# TC37X register map
File version: 1.0.0
CPU: CM4 r0p1, little endian, MPU, FPU, VTOR, 3 interrupt priority bits
Registers are 16-bit, read-write, reset 0x0 unless marked. A register's access mark holds for its fields unless they carry their own. Offsets are from the block's base; [hi:lo] are bit positions; lines under a group give offsets from that group; {n}, {i} and the like mark numbered series; 'fields as' and 'values as' point back to an identical list.

## SMU — ce_smu
Base 0xF0036800
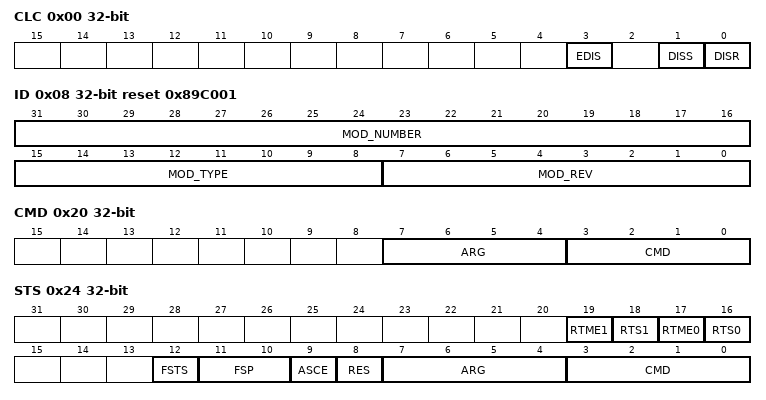
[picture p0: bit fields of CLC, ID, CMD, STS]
0x00 CLC 32-bit — Clock Control Register
  [3] EDIS — Sleep Mode Enable Control - EDIS
  [1] DISS ro — Module Disable Status Bit - DISS
  [0] DISR — Module Disable Request Bit - DISR
0x08 ID 32-bit ro reset 0x89C001 — Module Identification Register
  [31:16] MOD_NUMBER — Module Number Value - MOD_NUMBER
  [15:8] MOD_TYPE — Module Type - MOD_TYPE
  [7:0] MOD_REV — Module Revision Number - MOD_REV
0x20 CMD 32-bit wo — Command Register
  [7:4] ARG — Implements the SMU_core Command Interface. - ARG
  [3:0] CMD — Implements the SMU_core Command Interface. - CMD
0x24 STS 32-bit (reset mask 0xFFFFF3FF) — Status Register
  [19] RTME1 — Recovery Timer 1 Missed Event - RTME1
  [18] RTS1 — Recovery Timer 1 Status - RTS1
  [17] RTME0 — Recovery Timer 0 Missed Event - RTME0
  [16] RTS0 — Recovery Timer 0 Status - RTS0
  [12] FSTS — Fault State Timing Status - FSTS
  [11:10] FSP ro — Fault Signaling Protocol status - FSP
  [9] ASCE — Alarm Status Clear Enable - ASCE
  [8] RES — Result of last received command - RES
  [7:4] ARG — Last command argument received - ARG
  [3:0] CMD — Last command received - CMD
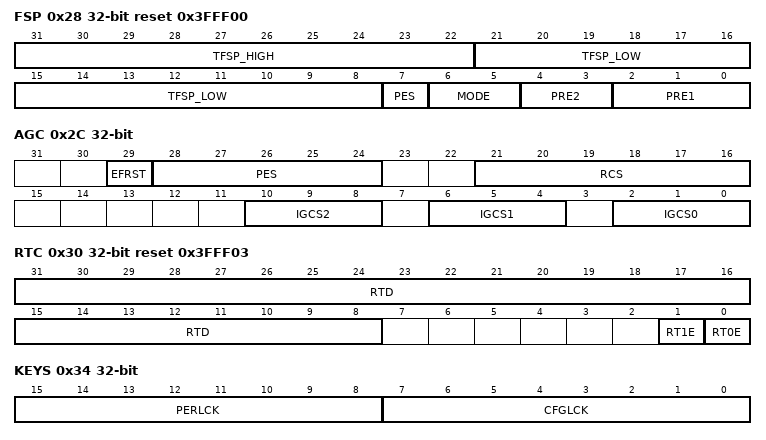
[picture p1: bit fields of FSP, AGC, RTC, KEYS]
0x28 FSP 32-bit reset 0x3FFF00 — Fault Signaling Protocol
  [31:22] TFSP_HIGH — Specifies the FSP fault state duration - TFSP_HIGH
  [21:8] TFSP_LOW ro — Specifies the FSP fault state duration - TFSP_LOW
  [7] PES — Port Emergency Stop (PES) - PES
  [6:5] MODE — Fault Signaling Protocol configuration - MODE
  [4:3] PRE2 — Prescaler2 - PRE2
  [2:0] PRE1 — Prescaler1 - PRE1
0x2C AGC 32-bit — Alarm Global Configuration
  [29] EFRST — Enable FAULT to RUN State Transition - EFRST
  [28:24] PES — Port Emergency Stop - PES
  [21:16] RCS — CPU Reset Configuration Set - RCS
  [10:8] IGCS2 — Interrupt Generation Configuration Set 2 - IGCS2
  [6:4] IGCS1 — Interrupt Generation Configuration Set 1 - IGCS1
  [2:0] IGCS0 — Interrupt Generation Configuration Set 0 - IGCS0
0x30 RTC 32-bit reset 0x3FFF03 — Recovery Timer Configuration
  [31:8] RTD — Recovery Timer Duration - RTD
  [1] RT1E — RT1 Enable Bit - RT1E
  [0] RT0E — RT0 Enable Bit - RT0E
0x34 KEYS 32-bit — Key Register
  [15:8] PERLCK — Permanent Lock - PERLCK
  [7:0] CFGLCK — Configuration Lock - CFGLCK
0x38 DBG 32-bit ro — Debug Register
  [1:0] SSM — Running state of the SMU_core State Machine - SSM
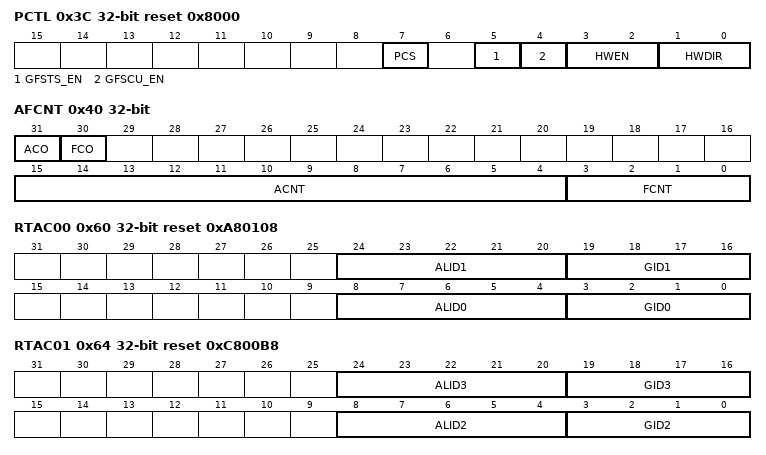
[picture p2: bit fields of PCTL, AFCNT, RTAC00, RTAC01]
0x3C PCTL 32-bit reset 0x8000 — Port Control
  [7] PCS — PAD Configuration Select - PCS
  [5] GFSTS_EN — Glitch Filter for ErrorPin SMU_FSP0 to register SMU_STS enable - GFSTS_EN
  [4] GFSCU_EN — Glitch Filter for ErrorPin SMU_FSP0 to SCU enable - GFSCU_EN
  [3:2] HWEN — Port Enable - HWEN
  [1:0] HWDIR — Port Direction. - HWDIR
0x40 AFCNT 32-bit ro — Alarm and Fault Counter
  [31] ACO — Alarm Counter Overflow. - ACO
  [30] FCO — Fault Counter Overflow. - FCO
  [15:4] ACNT — Alarm Counter. - ACNT
  [3:0] FCNT — Fault Counter. - FCNT
0x60 RTAC00 32-bit reset 0xA80108 — Recovery Timer 0 Alarm Configuration 0
  [24:20] ALID1 — Alarm Identifier 1. - ALID1
  [19:16] GID1 — Group Index 1. - GID1
  [8:4] ALID0 — Alarm Identifier 0. - ALID0
  [3:0] GID0 — Group Index 0. - GID0
0x64 RTAC01 32-bit reset 0xC800B8 — Recovery Timer 0 Alarm Configuration 1
  [24:20] ALID3 — Alarm Identifier 1. - ALID3
  [19:16] GID3 — Group Index 3. - GID3
  [8:4] ALID2 — Alarm Identifier 0. - ALID2
  [3:0] GID2 — Group Index 2. - GID2
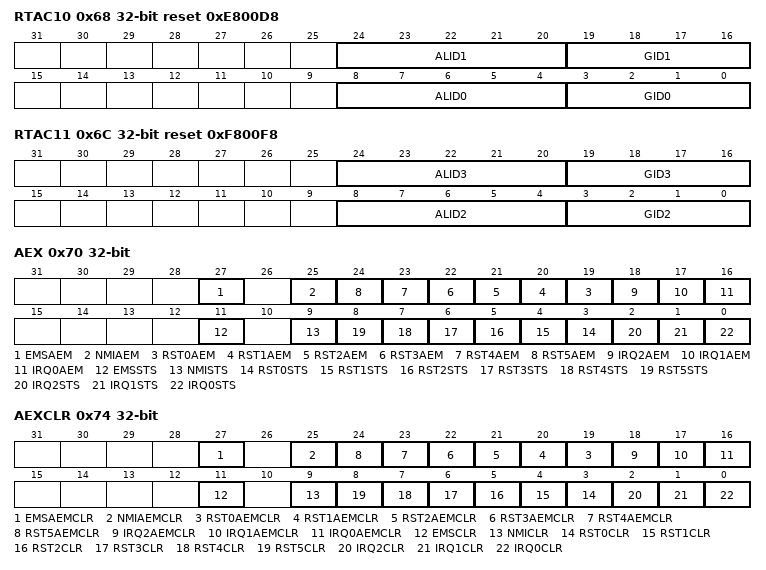
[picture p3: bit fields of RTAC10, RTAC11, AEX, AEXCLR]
0x68 RTAC10 32-bit reset 0xE800D8 — Recovery Timer 1 Alarm Configuration 0
  fields as RTAC00
0x6C RTAC11 32-bit reset 0xF800F8 — Recovery Timer 1 Alarm Configuration 1
  [24:20] ALID3 — Alarm Identifier 3. - ALID3
  [19:16] GID3 — Group Index 3. - GID3
  [8:4] ALID2 — Alarm Identifier 2. - ALID2
  [3:0] GID2 — Group Index 2. - GID2
0x70 AEX 32-bit ro — Alarm Executed Status Register
  [27] EMSAEM — EMS AEM - EMSAEM
  [25] NMIAEM — NMI AEM - NMIAEM
  [n+19] RST{n}AEM (n=0..5) — RST{n} AEM - RST{n}AEM
  [18] IRQ2AEM — IRQ2 AEM - IRQ2AEM
  [17] IRQ1AEM — IRQ1 AEM - IRQ1AEM
  [16] IRQ0AEM — IRQ0 AEM - IRQ0AEM
  [11] EMSSTS — EMS Request Status - EMSSTS
  [9] NMISTS — NMI Request Status - NMISTS
  [n+3] RST{n}STS (n=0..5) — RST{n} Request Status - RST{n}STS
  [2] IRQ2STS — IRQ2 Request Status - IRQ2STS
  [1] IRQ1STS — IRQ1 Request Status - IRQ1STS
  [0] IRQ0STS — IRQ0 Request Status - IRQ0STS
0x74 AEXCLR 32-bit wo — Alarm Executed Status Clear Register
  [27] EMSAEMCLR — EMS AEM Status Clear - EMSAEMCLR
  [25] NMIAEMCLR — NMI AEM Status Clear - NMIAEMCLR
  [n+19] RST{n}AEMCLR (n=0..5) — RST{n} AEM Status Clear - RST{n}AEMCLR
  [18] IRQ2AEMCLR — IRQ2 AEM Status Clear - IRQ2AEMCLR
  [17] IRQ1AEMCLR — IRQ1 AEM Status Clear - IRQ1AEMCLR
  [16] IRQ0AEMCLR — IRQ0 AEM Status Clear - IRQ0AEMCLR
  [11] EMSCLR — EMS Request Status Clear - EMSCLR
  [9] NMICLR — NMI Request Status Clear - NMICLR
  [n+3] RST{n}CLR (n=0..5) — RST{n} Request Status Clear - RST{n}CLR
  [2] IRQ2CLR — IRQ2 Request Status Clear - IRQ2CLR
  [1] IRQ1CLR — IRQ1 Request Status Clear - IRQ1CLR
  [0] IRQ0CLR — IRQ0 Request Status Clear - IRQ0CLR
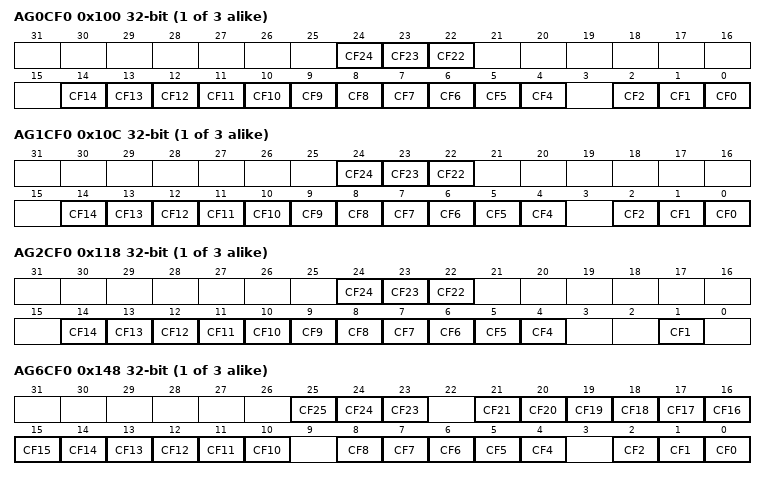
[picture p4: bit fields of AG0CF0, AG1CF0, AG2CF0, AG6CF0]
{0x100+4i} AG0CF{i} 32-bit (i=0..2) — Alarm Configuration Register
  [24] CF24 — Configuration flag x (x=0-2) for alarm 24 belonging to alarm group i. - CF24
  [23] CF23 — Configuration flag x (x=0-2) for alarm 23 belonging to alarm group i. - CF23
  [22] CF22 — Configuration flag x (x=0-2) for alarm 22 belonging to alarm group i. - CF22
  [n] CF{n} (n=4..14) — Configuration flag x (x=0-2) for alarm {n} belonging to alarm group i. - CF{n}
  [2] CF2 — Configuration flag x (x=0-2) for alarm 2 belonging to alarm group i. - CF2
  [1] CF1 — Configuration flag x (x=0-2) for alarm 1 belonging to alarm group i. - CF1
  [0] CF0 — Configuration flag x (x=0-2) for alarm 0 belonging to alarm group i. - CF0
{0x10C+4i} AG1CF{i} 32-bit (i=0..2) — Alarm Configuration Register
  fields as AG0CF0
{0x118+4i} AG2CF{i} 32-bit (i=0..2) — Alarm Configuration Register
  [24] CF24 — Configuration flag x (x=0-2) for alarm 24 belonging to alarm group i. - CF24
  [23] CF23 — Configuration flag x (x=0-2) for alarm 23 belonging to alarm group i. - CF23
  [22] CF22 — Configuration flag x (x=0-2) for alarm 22 belonging to alarm group i. - CF22
  [n] CF{n} (n=4..14) — Configuration flag x (x=0-2) for alarm {n} belonging to alarm group i. - CF{n}
  [1] CF1 — Configuration flag x (x=0-2) for alarm 1 belonging to alarm group i. - CF1
{0x100+0xC*i} AG{i}CF0 32-bit ro (i=3..5) — Alarm Configuration Register
{0x104+0xC*i} AG{i}CF1 32-bit ro (i=3..5) — Alarm Configuration Register
{0x108+0xC*i} AG{i}CF2 32-bit ro (i=3..5) — Alarm Configuration Register
{0x148+4i} AG6CF{i} 32-bit (i=0..2) — Alarm Configuration Register
  [25] CF25 — Configuration flag x (x=0-2) for alarm 25 belonging to alarm group i. - CF25
  [24] CF24 — Configuration flag x (x=0-2) for alarm 24 belonging to alarm group i. - CF24
  [23] CF23 — Configuration flag x (x=0-2) for alarm 23 belonging to alarm group i. - CF23
  [n] CF{n} (n=10..21) — Configuration flag x (x=0-2) for alarm {n} belonging to alarm group i. - CF{n}
  [n] CF{n} (n=4..8) — Configuration flag x (x=0-2) for alarm {n} belonging to alarm group i. - CF{n}
  [2] CF2 — Configuration flag x (x=0-2) for alarm 2 belonging to alarm group i. - CF2
  [1] CF1 — Configuration flag x (x=0-2) for alarm 1 belonging to alarm group i. - CF1
  [0] CF0 — Configuration flag x (x=0-2) for alarm 0 belonging to alarm group i. - CF0
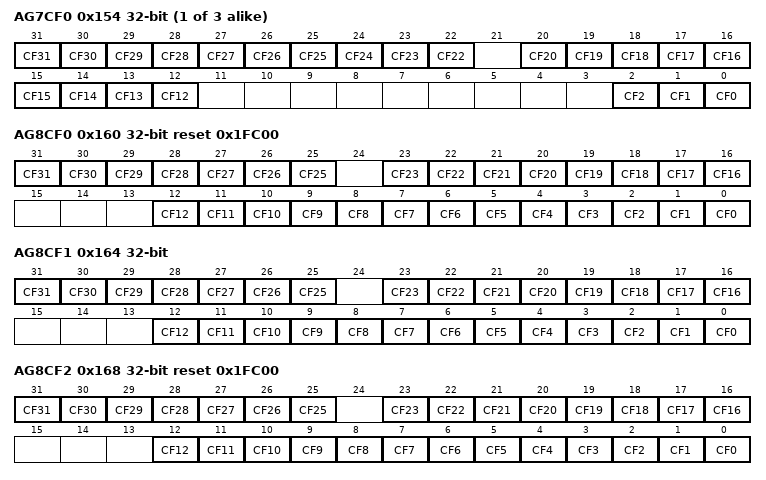
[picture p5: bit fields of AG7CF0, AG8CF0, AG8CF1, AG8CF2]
{0x154+4i} AG7CF{i} 32-bit (i=0..2) — Alarm Configuration Register
  [n] CF{n} (n=22..31) — Configuration flag x (x=0-2) for alarm {n} belonging to alarm group i. - CF{n}
  [n] CF{n} (n=12..20) — Configuration flag x (x=0-2) for alarm {n} belonging to alarm group i. - CF{n}
  [2] CF2 — Configuration flag x (x=0-2) for alarm 2 belonging to alarm group i. - CF2
  [1] CF1 — Configuration flag x (x=0-2) for alarm 1 belonging to alarm group i. - CF1
  [0] CF0 — Configuration flag x (x=0-2) for alarm 0 belonging to alarm group i. - CF0
0x160 AG8CF0 32-bit reset 0x1FC00 — Alarm Configuration Register
  [n] CF{n} (n=25..31) — Configuration flag x (x=0-2) for alarm {n} belonging to alarm group i. - CF{n}
  [n] CF{n} (n=16..23) — Configuration flag x (x=0-2) for alarm {n} belonging to alarm group i. - CF{n}
  [n] CF{n} (n=0..12) — Configuration flag x (x=0-2) for alarm {n} belonging to alarm group i. - CF{n}
0x164 AG8CF1 32-bit — Alarm Configuration Register
  fields as AG8CF0
0x168 AG8CF2 32-bit reset 0x1FC00 — Alarm Configuration Register
  fields as AG8CF0
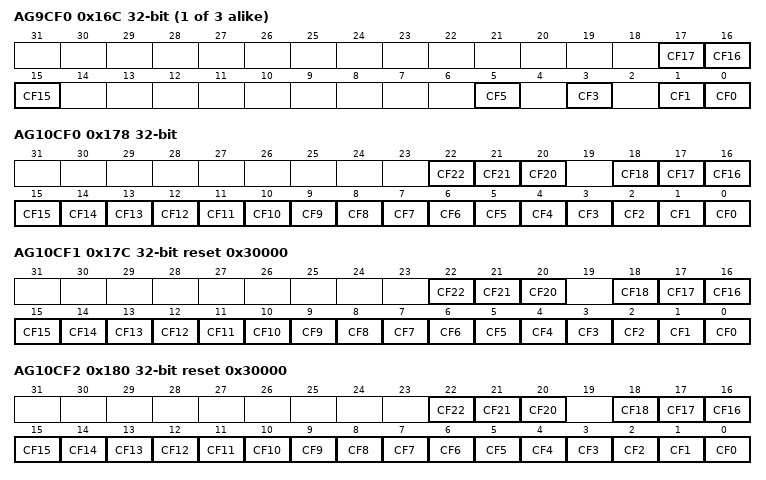
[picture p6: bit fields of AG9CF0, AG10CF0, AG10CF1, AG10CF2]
{0x16C+4i} AG9CF{i} 32-bit (i=0..2) — Alarm Configuration Register
  [17] CF17 — Configuration flag x (x=0-2) for alarm 17 belonging to alarm group i. - CF17
  [16] CF16 — Configuration flag x (x=0-2) for alarm 16 belonging to alarm group i. - CF16
  [15] CF15 — Configuration flag x (x=0-2) for alarm 15 belonging to alarm group i. - CF15
  [5] CF5 — Configuration flag x (x=0-2) for alarm 5 belonging to alarm group i. - CF5
  [3] CF3 — Configuration flag x (x=0-2) for alarm 3 belonging to alarm group i. - CF3
  [1] CF1 — Configuration flag x (x=0-2) for alarm 1 belonging to alarm group i. - CF1
  [0] CF0 — Configuration flag x (x=0-2) for alarm 0 belonging to alarm group i. - CF0
0x178 AG10CF0 32-bit — Alarm Configuration Register
  [22] CF22 — Configuration flag x (x=0-2) for alarm 22 belonging to alarm group i. - CF22
  [21] CF21 — Configuration flag x (x=0-2) for alarm 21 belonging to alarm group i. - CF21
  [20] CF20 — Configuration flag x (x=0-2) for alarm 20 belonging to alarm group i. - CF20
  [n] CF{n} (n=0..18) — Configuration flag x (x=0-2) for alarm {n} belonging to alarm group i. - CF{n}
0x17C AG10CF1 32-bit reset 0x30000 — Alarm Configuration Register
  fields as AG10CF0
0x180 AG10CF2 32-bit reset 0x30000 — Alarm Configuration Register
  fields as AG10CF0
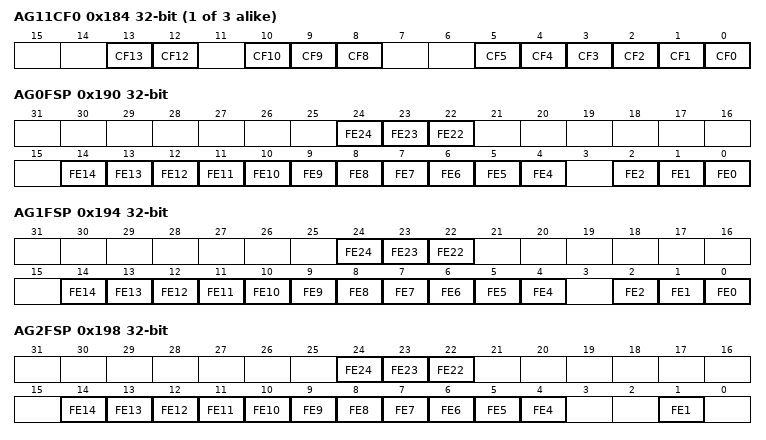
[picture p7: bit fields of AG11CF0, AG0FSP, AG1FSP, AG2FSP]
{0x184+4i} AG11CF{i} 32-bit (i=0..2) — Alarm Configuration Register
  [13] CF13 — Configuration flag x (x=0-2) for alarm 13 belonging to alarm group i. - CF13
  [12] CF12 — Configuration flag x (x=0-2) for alarm 12 belonging to alarm group i. - CF12
  [10] CF10 — Configuration flag x (x=0-2) for alarm 10 belonging to alarm group i. - CF10
  [9] CF9 — Configuration flag x (x=0-2) for alarm 9 belonging to alarm group i. - CF9
  [8] CF8 — Configuration flag x (x=0-2) for alarm 8 belonging to alarm group i. - CF8
  [n] CF{n} (n=0..5) — Configuration flag x (x=0-2) for alarm {n} belonging to alarm group i. - CF{n}
0x190 AG0FSP 32-bit — SMU_core FSP Configuration Register
  [24] FE24 — Fault signaling configuration flag for alarm 24 belonging to alarm group i. - FE24
  [23] FE23 — Fault signaling configuration flag for alarm 23 belonging to alarm group i. - FE23
  [22] FE22 — Fault signaling configuration flag for alarm 22 belonging to alarm group i. - FE22
  [n] FE{n} (n=4..14) — Fault signaling configuration flag for alarm {n} belonging to alarm group i. - FE{n}
  [2] FE2 — Fault signaling configuration flag for alarm 2 belonging to alarm group i. - FE2
  [1] FE1 — Fault signaling configuration flag for alarm 1 belonging to alarm group i. - FE1
  [0] FE0 — Fault signaling configuration flag for alarm 0 belonging to alarm group i. - FE0
0x194 AG1FSP 32-bit — SMU_core FSP Configuration Register
  fields as AG0FSP
0x198 AG2FSP 32-bit — SMU_core FSP Configuration Register
  [24] FE24 — Fault signaling configuration flag for alarm 24 belonging to alarm group i. - FE24
  [23] FE23 — Fault signaling configuration flag for alarm 23 belonging to alarm group i. - FE23
  [22] FE22 — Fault signaling configuration flag for alarm 22 belonging to alarm group i. - FE22
  [n] FE{n} (n=4..14) — Fault signaling configuration flag for alarm {n} belonging to alarm group i. - FE{n}
  [1] FE1 — Fault signaling configuration flag for alarm 1 belonging to alarm group i. - FE1
{0x190+4i} AG{i}FSP 32-bit ro (i=3..5) — SMU_core FSP Configuration Register
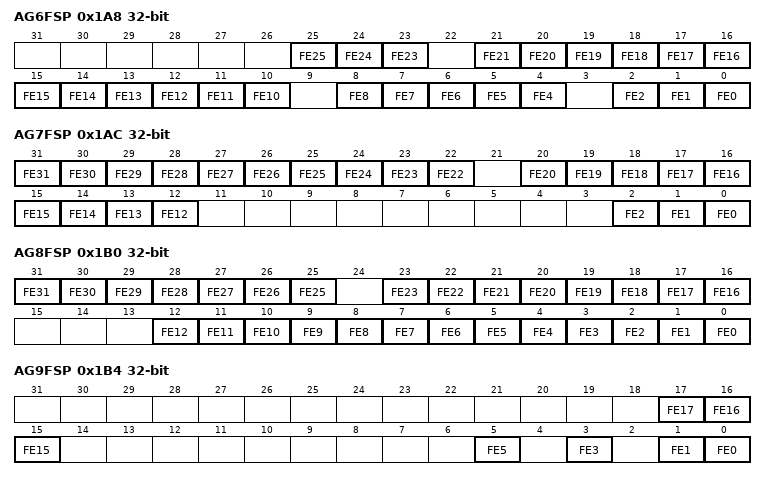
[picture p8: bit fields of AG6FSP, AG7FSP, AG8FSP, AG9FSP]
0x1A8 AG6FSP 32-bit — SMU_core FSP Configuration Register
  [25] FE25 — Fault signaling configuration flag for alarm 25 belonging to alarm group i. - FE25
  [24] FE24 — Fault signaling configuration flag for alarm 24 belonging to alarm group i. - FE24
  [23] FE23 — Fault signaling configuration flag for alarm 23 belonging to alarm group i. - FE23
  [n] FE{n} (n=10..21) — Fault signaling configuration flag for alarm {n} belonging to alarm group i. - FE{n}
  [n] FE{n} (n=4..8) — Fault signaling configuration flag for alarm {n} belonging to alarm group i. - FE{n}
  [2] FE2 — Fault signaling configuration flag for alarm 2 belonging to alarm group i. - FE2
  [1] FE1 — Fault signaling configuration flag for alarm 1 belonging to alarm group i. - FE1
  [0] FE0 — Fault signaling configuration flag for alarm 0 belonging to alarm group i. - FE0
0x1AC AG7FSP 32-bit — SMU_core FSP Configuration Register
  [n] FE{n} (n=22..31) — Fault signaling configuration flag for alarm {n} belonging to alarm group i. - FE{n}
  [n] FE{n} (n=12..20) — Fault signaling configuration flag for alarm {n} belonging to alarm group i. - FE{n}
  [2] FE2 — Fault signaling configuration flag for alarm 2 belonging to alarm group i. - FE2
  [1] FE1 — Fault signaling configuration flag for alarm 1 belonging to alarm group i. - FE1
  [0] FE0 — Fault signaling configuration flag for alarm 0 belonging to alarm group i. - FE0
0x1B0 AG8FSP 32-bit — SMU_core FSP Configuration Register
  [n] FE{n} (n=25..31) — Fault signaling configuration flag for alarm {n} belonging to alarm group i. - FE{n}
  [n] FE{n} (n=16..23) — Fault signaling configuration flag for alarm {n} belonging to alarm group i. - FE{n}
  [n] FE{n} (n=0..12) — Fault signaling configuration flag for alarm {n} belonging to alarm group i. - FE{n}
0x1B4 AG9FSP 32-bit — SMU_core FSP Configuration Register
  [17] FE17 — Fault signaling configuration flag for alarm 17 belonging to alarm group i. - FE17
  [16] FE16 — Fault signaling configuration flag for alarm 16 belonging to alarm group i. - FE16
  [15] FE15 — Fault signaling configuration flag for alarm 15 belonging to alarm group i. - FE15
  [5] FE5 — Fault signaling configuration flag for alarm 5 belonging to alarm group i. - FE5
  [3] FE3 — Fault signaling configuration flag for alarm 3 belonging to alarm group i. - FE3
  [1] FE1 — Fault signaling configuration flag for alarm 1 belonging to alarm group i. - FE1
  [0] FE0 — Fault signaling configuration flag for alarm 0 belonging to alarm group i. - FE0
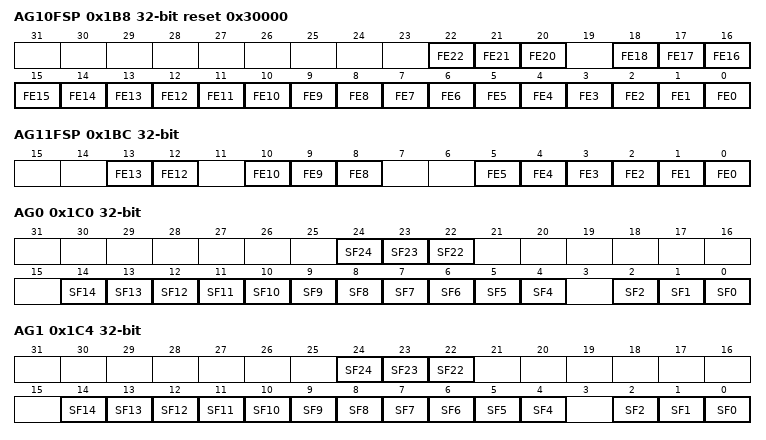
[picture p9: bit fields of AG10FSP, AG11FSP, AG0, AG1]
0x1B8 AG10FSP 32-bit reset 0x30000 — SMU_core FSP Configuration Register
  [22] FE22 — Fault signaling configuration flag for alarm 22 belonging to alarm group i. - FE22
  [21] FE21 — Fault signaling configuration flag for alarm 21 belonging to alarm group i. - FE21
  [20] FE20 — Fault signaling configuration flag for alarm 20 belonging to alarm group i. - FE20
  [n] FE{n} (n=0..18) — Fault signaling configuration flag for alarm {n} belonging to alarm group i. - FE{n}
0x1BC AG11FSP 32-bit — SMU_core FSP Configuration Register
  [13] FE13 — Fault signaling configuration flag for alarm 13 belonging to alarm group i. - FE13
  [12] FE12 — Fault signaling configuration flag for alarm 12 belonging to alarm group i. - FE12
  [10] FE10 — Fault signaling configuration flag for alarm 10 belonging to alarm group i. - FE10
  [9] FE9 — Fault signaling configuration flag for alarm 9 belonging to alarm group i. - FE9
  [8] FE8 — Fault signaling configuration flag for alarm 8 belonging to alarm group i. - FE8
  [n] FE{n} (n=0..5) — Fault signaling configuration flag for alarm {n} belonging to alarm group i. - FE{n}
0x1C0 AG0 32-bit — Alarm Status Register
  [24] SF24 — Status flag for alarm 24 belonging to alarm group i. - SF24
  [23] SF23 — Status flag for alarm 23 belonging to alarm group i. - SF23
  [22] SF22 — Status flag for alarm 22 belonging to alarm group i. - SF22
  [n] SF{n} (n=4..14) — Status flag for alarm {n} belonging to alarm group i. - SF{n}
  [2] SF2 — Status flag for alarm 2 belonging to alarm group i. - SF2
  [1] SF1 — Status flag for alarm 1 belonging to alarm group i. - SF1
  [0] SF0 — Status flag for alarm 0 belonging to alarm group i. - SF0
0x1C4 AG1 32-bit — Alarm Status Register
  fields as AG0
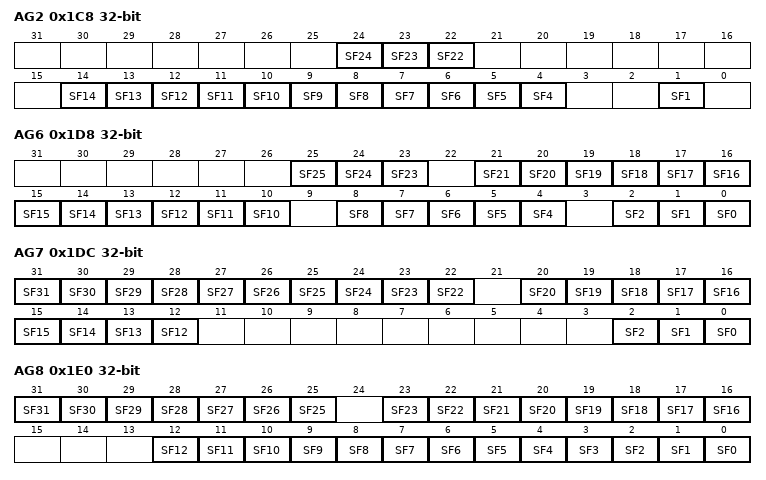
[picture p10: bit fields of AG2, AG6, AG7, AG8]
0x1C8 AG2 32-bit — Alarm Status Register
  [24] SF24 — Status flag for alarm 24 belonging to alarm group i. - SF24
  [23] SF23 — Status flag for alarm 23 belonging to alarm group i. - SF23
  [22] SF22 — Status flag for alarm 22 belonging to alarm group i. - SF22
  [n] SF{n} (n=4..14) — Status flag for alarm {n} belonging to alarm group i. - SF{n}
  [1] SF1 — Status flag for alarm 1 belonging to alarm group i. - SF1
{0x1C0+4i} AG{i} 32-bit ro (i=3..5) — Alarm Status Register
0x1D8 AG6 32-bit — Alarm Status Register
  [25] SF25 — Status flag for alarm 25 belonging to alarm group i. - SF25
  [24] SF24 — Status flag for alarm 24 belonging to alarm group i. - SF24
  [23] SF23 — Status flag for alarm 23 belonging to alarm group i. - SF23
  [n] SF{n} (n=10..21) — Status flag for alarm {n} belonging to alarm group i. - SF{n}
  [n] SF{n} (n=4..8) — Status flag for alarm {n} belonging to alarm group i. - SF{n}
  [2] SF2 — Status flag for alarm 2 belonging to alarm group i. - SF2
  [1] SF1 — Status flag for alarm 1 belonging to alarm group i. - SF1
  [0] SF0 — Status flag for alarm 0 belonging to alarm group i. - SF0
0x1DC AG7 32-bit — Alarm Status Register
  [n] SF{n} (n=22..31) — Status flag for alarm {n} belonging to alarm group i. - SF{n}
  [n] SF{n} (n=12..20) — Status flag for alarm {n} belonging to alarm group i. - SF{n}
  [2] SF2 — Status flag for alarm 2 belonging to alarm group i. - SF2
  [1] SF1 — Status flag for alarm 1 belonging to alarm group i. - SF1
  [0] SF0 — Status flag for alarm 0 belonging to alarm group i. - SF0
0x1E0 AG8 32-bit — Alarm Status Register
  [n] SF{n} (n=25..31) — Status flag for alarm {n} belonging to alarm group i. - SF{n}
  [n] SF{n} (n=16..23) — Status flag for alarm {n} belonging to alarm group i. - SF{n}
  [n] SF{n} (n=0..12) — Status flag for alarm {n} belonging to alarm group i. - SF{n}
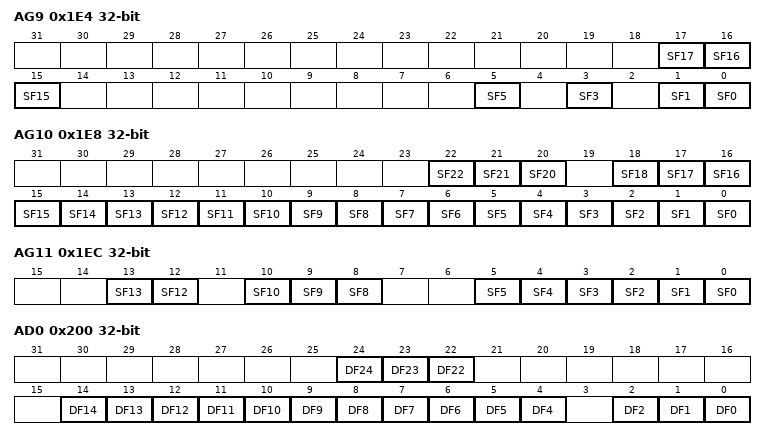
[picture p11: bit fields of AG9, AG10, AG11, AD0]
0x1E4 AG9 32-bit — Alarm Status Register
  [17] SF17 — Status flag for alarm 17 belonging to alarm group i. - SF17
  [16] SF16 — Status flag for alarm 16 belonging to alarm group i. - SF16
  [15] SF15 — Status flag for alarm 15 belonging to alarm group i. - SF15
  [5] SF5 — Status flag for alarm 5 belonging to alarm group i. - SF5
  [3] SF3 — Status flag for alarm 3 belonging to alarm group i. - SF3
  [1] SF1 — Status flag for alarm 1 belonging to alarm group i. - SF1
  [0] SF0 — Status flag for alarm 0 belonging to alarm group i. - SF0
0x1E8 AG10 32-bit — Alarm Status Register
  [22] SF22 — Status flag for alarm 22 belonging to alarm group i. - SF22
  [21] SF21 — Status flag for alarm 21 belonging to alarm group i. - SF21
  [20] SF20 — Status flag for alarm 20 belonging to alarm group i. - SF20
  [n] SF{n} (n=0..18) — Status flag for alarm {n} belonging to alarm group i. - SF{n}
0x1EC AG11 32-bit — Alarm Status Register
  [13] SF13 — Status flag for alarm 13 belonging to alarm group i. - SF13
  [12] SF12 — Status flag for alarm 12 belonging to alarm group i. - SF12
  [10] SF10 — Status flag for alarm 10 belonging to alarm group i. - SF10
  [9] SF9 — Status flag for alarm 9 belonging to alarm group i. - SF9
  [8] SF8 — Status flag for alarm 8 belonging to alarm group i. - SF8
  [n] SF{n} (n=0..5) — Status flag for alarm {n} belonging to alarm group i. - SF{n}
0x200 AD0 32-bit ro — Alarm Debug Register
  [24] DF24 — Diagnosis flag for alarm 24 belonging to alarm group i. - DF24
  [23] DF23 — Diagnosis flag for alarm 23 belonging to alarm group i. - DF23
  [22] DF22 — Diagnosis flag for alarm 22 belonging to alarm group i. - DF22
  [n] DF{n} (n=4..14) — Diagnosis flag for alarm {n} belonging to alarm group i. - DF{n}
  [2] DF2 — Diagnosis flag for alarm 2 belonging to alarm group i. - DF2
  [1] DF1 — Diagnosis flag for alarm 1 belonging to alarm group i. - DF1
  [0] DF0 — Diagnosis flag for alarm 0 belonging to alarm group i. - DF0
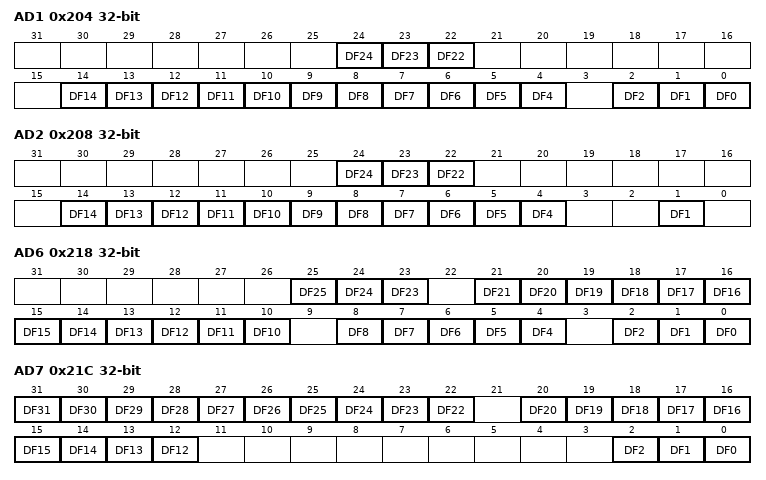
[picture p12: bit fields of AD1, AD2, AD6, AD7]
0x204 AD1 32-bit ro — Alarm Debug Register
  fields as AD0
0x208 AD2 32-bit ro — Alarm Debug Register
  [24] DF24 — Diagnosis flag for alarm 24 belonging to alarm group i. - DF24
  [23] DF23 — Diagnosis flag for alarm 23 belonging to alarm group i. - DF23
  [22] DF22 — Diagnosis flag for alarm 22 belonging to alarm group i. - DF22
  [n] DF{n} (n=4..14) — Diagnosis flag for alarm {n} belonging to alarm group i. - DF{n}
  [1] DF1 — Diagnosis flag for alarm 1 belonging to alarm group i. - DF1
{0x200+4i} AD{i} 32-bit ro (i=3..5) — Alarm Debug Register
0x218 AD6 32-bit ro — Alarm Debug Register
  [25] DF25 — Diagnosis flag for alarm 25 belonging to alarm group i. - DF25
  [24] DF24 — Diagnosis flag for alarm 24 belonging to alarm group i. - DF24
  [23] DF23 — Diagnosis flag for alarm 23 belonging to alarm group i. - DF23
  [n] DF{n} (n=10..21) — Diagnosis flag for alarm {n} belonging to alarm group i. - DF{n}
  [n] DF{n} (n=4..8) — Diagnosis flag for alarm {n} belonging to alarm group i. - DF{n}
  [2] DF2 — Diagnosis flag for alarm 2 belonging to alarm group i. - DF2
  [1] DF1 — Diagnosis flag for alarm 1 belonging to alarm group i. - DF1
  [0] DF0 — Diagnosis flag for alarm 0 belonging to alarm group i. - DF0
0x21C AD7 32-bit ro — Alarm Debug Register
  [n] DF{n} (n=22..31) — Diagnosis flag for alarm {n} belonging to alarm group i. - DF{n}
  [n] DF{n} (n=12..20) — Diagnosis flag for alarm {n} belonging to alarm group i. - DF{n}
  [2] DF2 — Diagnosis flag for alarm 2 belonging to alarm group i. - DF2
  [1] DF1 — Diagnosis flag for alarm 1 belonging to alarm group i. - DF1
  [0] DF0 — Diagnosis flag for alarm 0 belonging to alarm group i. - DF0
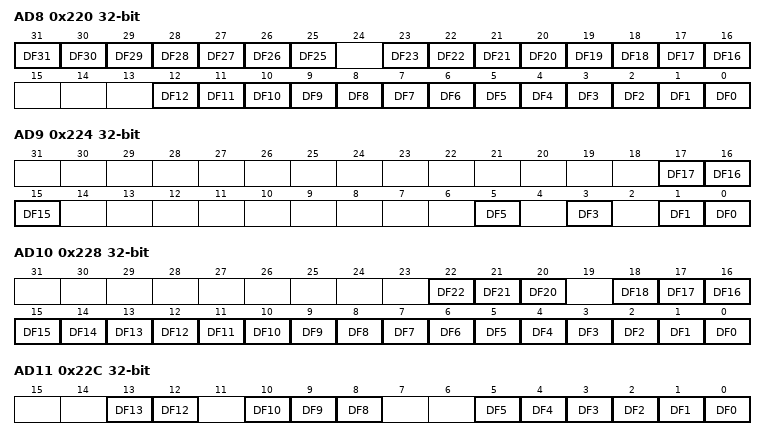
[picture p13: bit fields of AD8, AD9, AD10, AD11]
0x220 AD8 32-bit ro — Alarm Debug Register
  [n] DF{n} (n=25..31) — Diagnosis flag for alarm {n} belonging to alarm group i. - DF{n}
  [n] DF{n} (n=16..23) — Diagnosis flag for alarm {n} belonging to alarm group i. - DF{n}
  [n] DF{n} (n=0..12) — Diagnosis flag for alarm {n} belonging to alarm group i. - DF{n}
0x224 AD9 32-bit ro — Alarm Debug Register
  [17] DF17 — Diagnosis flag for alarm 17 belonging to alarm group i. - DF17
  [16] DF16 — Diagnosis flag for alarm 16 belonging to alarm group i. - DF16
  [15] DF15 — Diagnosis flag for alarm 15 belonging to alarm group i. - DF15
  [5] DF5 — Diagnosis flag for alarm 5 belonging to alarm group i. - DF5
  [3] DF3 — Diagnosis flag for alarm 3 belonging to alarm group i. - DF3
  [1] DF1 — Diagnosis flag for alarm 1 belonging to alarm group i. - DF1
  [0] DF0 — Diagnosis flag for alarm 0 belonging to alarm group i. - DF0
0x228 AD10 32-bit ro — Alarm Debug Register
  [22] DF22 — Diagnosis flag for alarm 22 belonging to alarm group i. - DF22
  [21] DF21 — Diagnosis flag for alarm 21 belonging to alarm group i. - DF21
  [20] DF20 — Diagnosis flag for alarm 20 belonging to alarm group i. - DF20
  [n] DF{n} (n=0..18) — Diagnosis flag for alarm {n} belonging to alarm group i. - DF{n}
0x22C AD11 32-bit ro — Alarm Debug Register
  [13] DF13 — Diagnosis flag for alarm 13 belonging to alarm group i. - DF13
  [12] DF12 — Diagnosis flag for alarm 12 belonging to alarm group i. - DF12
  [10] DF10 — Diagnosis flag for alarm 10 belonging to alarm group i. - DF10
  [9] DF9 — Diagnosis flag for alarm 9 belonging to alarm group i. - DF9
  [8] DF8 — Diagnosis flag for alarm 8 belonging to alarm group i. - DF8
  [n] DF{n} (n=0..5) — Diagnosis flag for alarm {n} belonging to alarm group i. - DF{n}
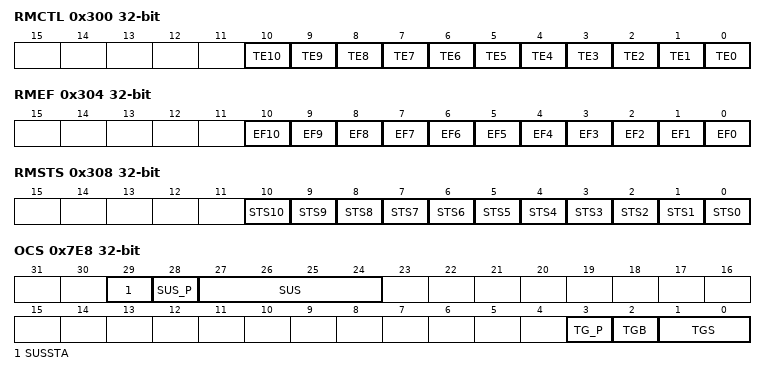
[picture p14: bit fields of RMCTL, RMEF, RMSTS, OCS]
0x300 RMCTL 32-bit — Register Monitor Control
  [n] TE{n} (n=0..10) — Test Enable. - TE{n}
0x304 RMEF 32-bit — Register Monitor Error Flags
  [n] EF{n} (n=0..10) — Status flag related to the different instances of the register monitor safety mechanism. - EF{n}
0x308 RMSTS 32-bit — Register Monitor Self Test Status
  [n] STS{n} (n=0..10) — Ready flag related to the different instances of the register monitor safety mechanism. - STS{n}
0x7E8 OCS 32-bit — OCDS Control and Status
  [29] SUSSTA ro — Suspend State - SUSSTA
  [28] SUS_P wo — SUS Write Protection - SUS_P
  [27:24] SUS — OCDS Suspend Control - SUS
  [3] TG_P wo — TGS, TGB Write Protection - TG_P
  [2] TGB — OTGB0/1 Bus Select - TGB
  [1:0] TGS — Trigger Set for OTGB0/1 - TGS
0x7F8 ACCEN1 32-bit ro — SMU_core Access Enable Register 1
0x7FC ACCEN0 32-bit reset 0xFFFFFFFF — SMU_core Access Enable Register 0
  [n] EN{n} (n=0..31) — Access Enable for Master TAG ID {n} - EN{n}
